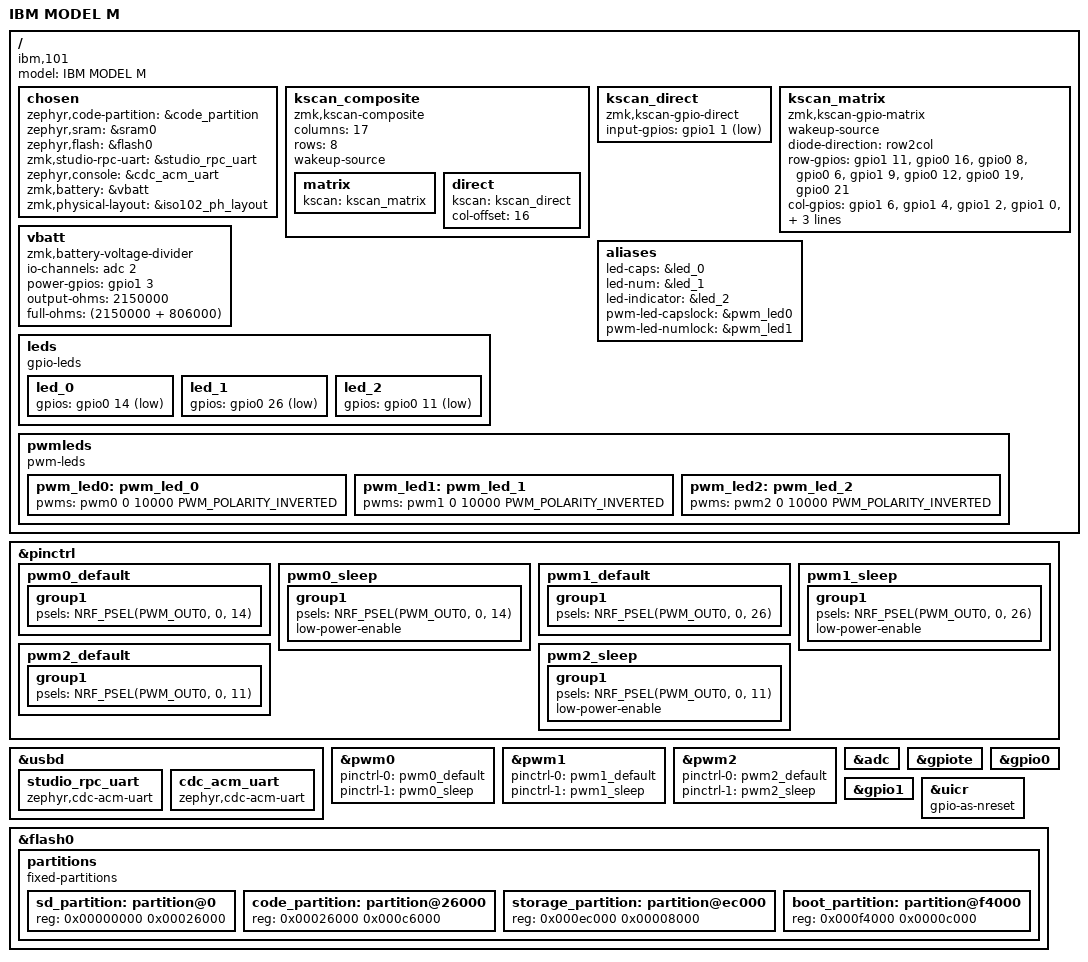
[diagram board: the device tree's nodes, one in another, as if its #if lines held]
/*
* Copyright (c) 2023 The ZMK Contributers
* SPDX-Licencse-Identifier: MIT
*/

/dts-v1/;
#include <nordic/nrf52840_qiaa.dtsi>
#include <dt-bindings/zmk/matrix_transform.h>

#include "config.dtsi"
#ifdef DFU_IN_KEYMAP
#include "../../common/modelm_posmap_103.dtsi"
#define UNIFIED_KSCAN kscan_composite
#else
#include "../../common/modelm_posmap_102.dtsi"
#define UNIFIED_KSCAN kscan_matrix
#endif
#include "../../common/layouts/modelm_ansi101.dtsi"
#include "../../common/layouts/modelm_iso102.dtsi"
#include "../../common/layouts/modelm_ansi84.dtsi"
#include "../../common/layouts/modelm_iso85.dtsi"


/ {
    model = "IBM MODEL M";
    compatible = "ibm,101";

    chosen {
        zephyr,code-partition = &code_partition;
        zephyr,sram = &sram0;
        zephyr,flash = &flash0;
        zmk,studio-rpc-uart = &studio_rpc_uart;
        zephyr,console = &cdc_acm_uart;
        zmk,battery = &vbatt;
        zmk,physical-layout = &iso102_ph_layout;
    };

// Include DFU button if needed
#ifdef DFU_IN_KEYMAP
    // Combine matrix and direct GPIO to integrate DFU button neat the USB connector
    kscan_composite: kscan_composite {
        compatible = "zmk,kscan-composite";
        columns = <17>;
        rows = <8>;
        wakeup-source;

        // Include the matrix driver
        matrix {
            kscan = <&kscan_matrix>;
        };

        // Include the direct GPIO driver...
        direct {
            kscan = <&kscan_direct>;
            col-offset = <16>;
        };
    };

    kscan_direct: kscan_direct {
        compatible = "zmk,kscan-gpio-direct";
        // DFU button is on P1.01 GPIO-direct pin active-low, pull high
        input-gpios
            = <&gpio1 1 (GPIO_ACTIVE_LOW | GPIO_PULL_UP)> // DFU
            ;
        /*
         * A direct pin defined in the input-gpios property is considered a column
         * when used in a matrix transform; e.g. the 5th pin on the list can be referred to using RC(0,4).
         */
    };

#endif 

    kscan_matrix: kscan_matrix {
        compatible = "zmk,kscan-gpio-matrix";
        wakeup-source;
        diode-direction = "row2col";

        row-gpios
            = <&gpio1 11 (GPIO_OPEN_SOURCE)> // R0
            , <&gpio0 16 (GPIO_OPEN_SOURCE)> // R1
            , <&gpio0 8  (GPIO_OPEN_SOURCE)> // R2
            , <&gpio0 6  (GPIO_OPEN_SOURCE)> // R3
            , <&gpio1 9  (GPIO_OPEN_SOURCE)> // R4
            , <&gpio0 12 (GPIO_OPEN_SOURCE)> // R5
            , <&gpio0 19 (GPIO_OPEN_SOURCE)> // R6
            , <&gpio0 21 (GPIO_OPEN_SOURCE)> // R7
            ;

        col-gpios
            = <&gpio1 6  (GPIO_ACTIVE_HIGH | GPIO_PULL_DOWN)> // C0
            , <&gpio1 4  (GPIO_ACTIVE_HIGH | GPIO_PULL_DOWN)> // C1
            , <&gpio1 2  (GPIO_ACTIVE_HIGH | GPIO_PULL_DOWN)> // C2
            , <&gpio1 0  (GPIO_ACTIVE_HIGH | GPIO_PULL_DOWN)> // C3
            , <&gpio0 24 (GPIO_ACTIVE_HIGH | GPIO_PULL_DOWN)> // C4
            , <&gpio0 22 (GPIO_ACTIVE_HIGH | GPIO_PULL_DOWN)> // C5
            , <&gpio0 20 (GPIO_ACTIVE_HIGH | GPIO_PULL_DOWN)> // C6
            , <&gpio0 17 (GPIO_ACTIVE_HIGH | GPIO_PULL_DOWN)> // C7
            , <&gpio1 7  (GPIO_ACTIVE_HIGH | GPIO_PULL_DOWN)> // C8
            , <&gpio0 25 (GPIO_ACTIVE_HIGH | GPIO_PULL_DOWN)> // C9
            , <&gpio0 15 (GPIO_ACTIVE_HIGH | GPIO_PULL_DOWN)> // C10
            , <&gpio0 10 (GPIO_ACTIVE_HIGH | GPIO_PULL_DOWN)> // C11
            , <&gpio0 9  (GPIO_ACTIVE_HIGH | GPIO_PULL_DOWN)> // C12
            , <&gpio1 5  (GPIO_ACTIVE_HIGH | GPIO_PULL_DOWN)> // C13
            , <&gpio0 13 (GPIO_ACTIVE_HIGH | GPIO_PULL_DOWN)> // C14
            , <&gpio0 23 (GPIO_ACTIVE_HIGH | GPIO_PULL_DOWN)> // C15
            ;
    };

    vbatt: vbatt {
        compatible = "zmk,battery-voltage-divider";
        io-channels = <&adc 2>;
        power-gpios = <&gpio1 3 GPIO_ACTIVE_HIGH>;
        output-ohms = <2150000>;
        full-ohms = <(2150000 + 806000)>;
    };

    aliases {
		led-caps = &led_0;
		led-num = &led_1;
        /* Use led_2 as BLE/Battery blink indicator instead */
		//led-scroll = &led_2;
        led-indicator = &led_2;
    };

    leds {
        compatible = "gpio-leds";
        status = "okay";
        led_0: led_0 {
            gpios = <&gpio0 14 GPIO_ACTIVE_LOW>;
        };
        led_1: led_1 {
            gpios = <&gpio0 26 GPIO_ACTIVE_LOW>;
        };
        led_2: led_2 {
            gpios = <&gpio0 11 GPIO_ACTIVE_LOW>;
        };
    };

    aliases {
        pwm-led-capslock = &pwm_led0;
		pwm-led-numlock = &pwm_led1;
        //pwm-led-scrolllock = &pwm_led2;
    };

	pwmleds {
		compatible = "pwm-leds";
		pwm_led0: pwm_led_0 {
			pwms = <&pwm0 0 10000 PWM_POLARITY_INVERTED>;
		};

		pwm_led1: pwm_led_1 {
			pwms = <&pwm1 0 10000 PWM_POLARITY_INVERTED>;
		};

		pwm_led2: pwm_led_2 {
			pwms = <&pwm2 0 10000 PWM_POLARITY_INVERTED>;
		};
	};

};

&pinctrl {
	pwm0_default: pwm0_default {
        group1 {
            psels = <NRF_PSEL(PWM_OUT0, 0, 14)>;
        };
    };
	
    pwm0_sleep: pwm0_sleep {
        group1 {
            psels = <NRF_PSEL(PWM_OUT0, 0, 14)>;
            low-power-enable;
        };
    };

	pwm1_default: pwm1_default {
        group1 {
            psels = <NRF_PSEL(PWM_OUT0, 0, 26)>;
        };
    };
	
    pwm1_sleep: pwm1_sleep {
        group1 {
            psels = <NRF_PSEL(PWM_OUT0, 0, 26)>;
            low-power-enable;
        };
    };
	
	pwm2_default: pwm2_default {
        group1 {
            psels = <NRF_PSEL(PWM_OUT0, 0, 11)>;
        };
    };
	
    pwm2_sleep: pwm2_sleep {
        group1 {
            psels = <NRF_PSEL(PWM_OUT0, 0, 11)>;
            low-power-enable;
        };
    };

};

zephyr_udc0: &usbd {
    status = "okay";
    studio_rpc_uart: studio_rpc_uart {
        compatible = "zephyr,cdc-acm-uart";
    };
    cdc_acm_uart: cdc_acm_uart {
        compatible = "zephyr,cdc-acm-uart";
    };
};

&pwm0 {
    status = "okay";
    pinctrl-0 = <&pwm0_default>;
    pinctrl-1 = <&pwm0_sleep>;
    pinctrl-names = "default", "sleep";
};

&pwm1 {
    status = "okay";
    pinctrl-0 = <&pwm1_default>;
    pinctrl-1 = <&pwm1_sleep>;
    pinctrl-names = "default", "sleep";
};

&pwm2 {
    status = "okay";
    pinctrl-0 = <&pwm2_default>;
    pinctrl-1 = <&pwm2_sleep>;
    pinctrl-names = "default", "sleep";
};

&adc {
    status = "okay";
};

&gpiote {
    status = "okay";
};

&gpio0 {
    status = "okay";
};

&gpio1 {
    status = "okay";
};


/* CONFIG_GPIO_AS_PINRESET is deprecated use this instead */
&uicr {
    gpio-as-nreset;
};

&flash0 {
    /*
     * For more information, see:
     * http://docs.zephyrproject.org/latest/devices/dts/flash_partitions.html
     */
    partitions {
        compatible = "fixed-partitions";
        #address-cells = <1>;
        #size-cells = <1>;

        sd_partition: partition@0 {
            reg = <0x00000000 0x00026000>;
        };

        code_partition: partition@26000 {
            reg = <0x00026000 0x000c6000>;
        };

        /*
         * The flash starting at 0x000ec000 and ending at
         * 0x000f3fff is reserved for use by the application.
         */

        /*
         * Storage partition will be used by FCB/LittleFS/NVS
         * if enabled.
         */
        storage_partition: partition@ec000 {
            reg = <0x000ec000 0x00008000>;
        };

        boot_partition: partition@f4000 {
            reg = <0x000f4000 0x0000c000>;
        };
    };
};
